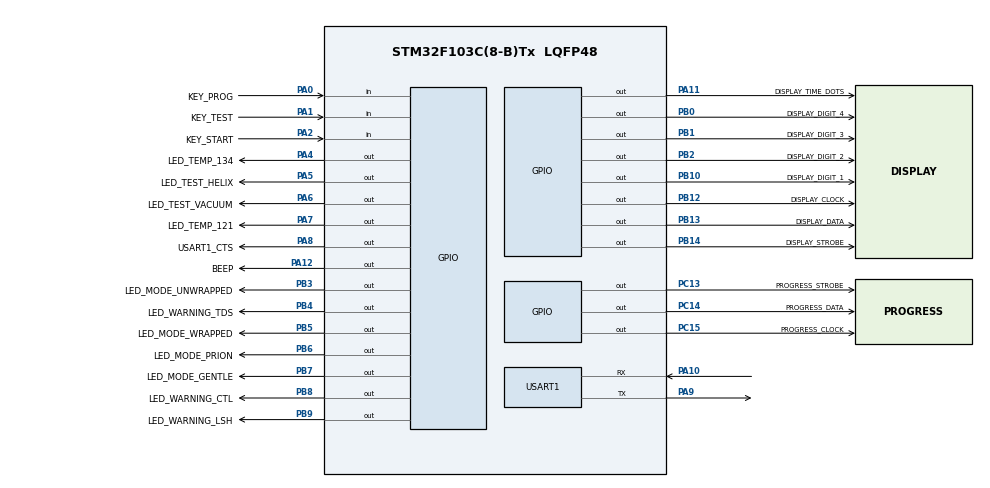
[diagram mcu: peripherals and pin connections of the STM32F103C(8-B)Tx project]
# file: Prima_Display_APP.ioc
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Dma.Request0=USART1_RX
Dma.USART1_RX.0.Direction=DMA_PERIPH_TO_MEMORY
Dma.USART1_RX.0.Instance=DMA1_Channel5
Dma.USART1_RX.0.MemDataAlignment=DMA_MDATAALIGN_BYTE
Dma.USART1_RX.0.MemInc=DMA_MINC_ENABLE
Dma.USART1_RX.0.Mode=DMA_NORMAL
Dma.USART1_RX.0.PeriphDataAlignment=DMA_PDATAALIGN_BYTE
Dma.USART1_RX.0.PeriphInc=DMA_PINC_DISABLE
Dma.USART1_RX.0.Priority=DMA_PRIORITY_LOW
FREERTOS.Queues01=qBeep,3,uint64_t,0,Dynamic,NULL,NULL;qSend,16,uint16_t,0,Dynamic,NULL,NULL;qReceive,16,uint16_t,0,Dynamic,NULL,NULL
FREERTOS.Tasks01=dispTask,0,128,StartDisplayTask,Default,NULL,Dynamic,NULL,NULL;dispBlinkTask,-3,128,StartDisplayBlinkTask,Default,NULL,Dynamic,NULL,NULL;dispSerialTask,-3,128,StartDisplaySerialReceiveTask,Default,NULL,Dynamic,NULL,NULL;buzzerTask,-3,128,StartBuzzerTask,Default,NULL,Dynamic,NULL,NULL
FREERTOS.configUSE_NEWLIB_REENTRANT=1
Mcu.Family=STM32F1
Mcu.Name=STM32F103C(8-B)Tx
Mcu.Package=LQFP48
NVIC.DMA1_Channel5_IRQn=true\:5\:0\:false\:false\:true\:true\:false\:true\:true
NVIC.PriorityGroup=NVIC_PRIORITYGROUP_4
NVIC.TIM3_IRQn=true\:15\:0\:false\:false\:true\:false\:false\:true\:true
NVIC.TimeBase=TIM3_IRQn
NVIC.TimeBaseIP=TIM3
NVIC.USART1_IRQn=true\:5\:0\:false\:false\:true\:true\:true\:true\:true
PA0-WKUP.GPIO_Label=KEY_PROG
PA0-WKUP.Signal=GPIO_Input
PA1.GPIO_Label=KEY_TEST
PA1.Signal=GPIO_Input
PA10.Mode=Asynchronous
PA10.Signal=USART1_RX
PA11.GPIO_Label=DISPLAY_TIME_DOTS
PA11.Signal=GPIO_Output
PA12.GPIO_Label=BEEP
PA12.Signal=GPIO_Output
PA13.Mode=Serial_Wire
PA13.Signal=SYS_JTMS-SWDIO
PA14.Mode=Serial_Wire
PA14.Signal=SYS_JTCK-SWCLK
PA2.GPIO_Label=KEY_START
PA2.Signal=GPIO_Input
PA4.GPIO_Label=LED_TEMP_134
PA4.Signal=GPIO_Output
PA5.GPIO_Label=LED_TEST_HELIX
PA5.Signal=GPIO_Output
PA6.GPIO_Label=LED_TEST_VACUUM
PA6.Signal=GPIO_Output
PA7.GPIO_Label=LED_TEMP_121
PA7.Signal=GPIO_Output
PA8.GPIO_Label=USART1_CTS
PA8.Signal=GPIO_Output
PA9.Mode=Asynchronous
PA9.Signal=USART1_TX
PB0.GPIO_Label=DISPLAY_DIGIT_4
PB0.Signal=GPIO_Output
PB1.GPIO_Label=DISPLAY_DIGIT_3
PB1.Signal=GPIO_Output
PB10.GPIO_Label=DISPLAY_DIGIT_1
PB10.Signal=GPIO_Output
PB12.GPIO_Label=DISPLAY_CLOCK
PB12.Signal=GPIO_Output
PB13.GPIO_Label=DISPLAY_DATA
PB13.Signal=GPIO_Output
PB14.GPIO_Label=DISPLAY_STROBE
PB14.Signal=GPIO_Output
PB2.GPIO_Label=DISPLAY_DIGIT_2
PB2.Signal=GPIO_Output
PB3.GPIO_Label=LED_MODE_UNWRAPPED
PB3.Signal=GPIO_Output
PB4.GPIO_Label=LED_WARNING_TDS
PB4.Signal=GPIO_Output
PB5.GPIO_Label=LED_MODE_WRAPPED
PB5.Signal=GPIO_Output
PB6.GPIO_Label=LED_MODE_PRION
PB6.Signal=GPIO_Output
PB7.GPIO_Label=LED_MODE_GENTLE
PB7.Signal=GPIO_Output
PB8.GPIO_Label=LED_WARNING_CTL
PB8.Signal=GPIO_Output
PB9.GPIO_Label=LED_WARNING_LSH
PB9.Signal=GPIO_Output
PC13-TAMPER-RTC.GPIO_Label=PROGRESS_STROBE
PC13-TAMPER-RTC.Signal=GPIO_Output
PC14-OSC32_IN.GPIO_Label=PROGRESS_DATA
PC14-OSC32_IN.Signal=GPIO_Output
PC15-OSC32_OUT.GPIO_Label=PROGRESS_CLOCK
PC15-OSC32_OUT.Signal=GPIO_Output
ProjectManager.HeapSize=0x200
ProjectManager.StackSize=0x400
ProjectManager.TargetToolchain=STM32CubeIDE
RCC.APB1Freq_Value=8000000
RCC.APB2Freq_Value=8000000
USART1.VirtualMode=VM_ASYNC
VP_FREERTOS_VS_CMSIS_V1.Mode=CMSIS_V1
VP_SYS_VS_tim3.Mode=TIM3
VP_TIM1_VS_ClockSourceINT.Mode=Internal
board=custom

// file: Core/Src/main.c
/* USER CODE BEGIN Header */
/**
  ******************************************************************************
  * @file           : main.c
  * @brief          : Main program body
  ******************************************************************************
  * @attention
  *
  * Copyright (c) 2022 STMicroelectronics.
  * All rights reserved.
  *
  * This software is licensed under terms that can be found in the LICENSE file
  * in the root directory of this software component.
  * If no LICENSE file comes with this software, it is provided AS-IS.
  *
  ******************************************************************************
  */
/* USER CODE END Header */
#include "main.h"

TIM_HandleTypeDef htim1;

UART_HandleTypeDef huart1;
DMA_HandleTypeDef hdma_usart1_rx;

osMessageQId qBeepHandle;
osMessageQId qSendHandle;
osMessageQId qReceiveHandle;

osThreadId dispTaskHandle;
osThreadId dispBlinkTaskHandle;
osThreadId dispSerialTaskHandle;
osThreadId buzzerTaskHandle;

void SystemClock_Config(void);
static void MX_GPIO_Init(void);
static void MX_DMA_Init(void);
static void MX_TIM1_Init(void);
static void MX_USART1_UART_Init(void);
void StartDisplayTask(void const * argument);
void StartDisplayBlinkTask(void const * argument);
void StartDisplaySerialReceiveTask(void const * argument);
void StartBuzzerTask(void const * argument);

/* USER CODE BEGIN 0 */

#define UART_BUFFER_SIZE 30
uint8_t UART_rxBuffer[UART_BUFFER_SIZE] = {0};

void HAL_UARTEx_RxEventCallback(UART_HandleTypeDef *huart, uint16_t Size) {
	//HAL_UART_Receive_DMA(p_activeUART, UART_rxBuffer, 3);

	HAL_UARTEx_ReceiveToIdle_DMA(huart, UART_rxBuffer, UART_BUFFER_SIZE); // Interrupt on receive buffer full or idle (end receive)
	__HAL_DMA_DISABLE_IT(&hdma_usart1_rx, DMA_IT_HT); // Disable half buffer received interrupt

	// Check for UART
	if (huart->Instance == huart1.Instance) {
		DisplaySerialReceive(UART_rxBuffer, Size);
	}

	// Receive again

}

/* USER CODE END 0 */

int main(void)
{

  /* MCU Configuration--------------------------------------------------------*/

  /* Reset of all peripherals, Initializes the Flash interface and the Systick. */
  HAL_Init();

  /* Configure the system clock */
  SystemClock_Config();

  /* Initialize all configured peripherals */
  MX_GPIO_Init();
  MX_DMA_Init();
  MX_TIM1_Init();
  MX_USART1_UART_Init();
  /* USER CODE BEGIN 2 */

  HAL_UARTEx_ReceiveToIdle_DMA(&huart1, UART_rxBuffer, UART_BUFFER_SIZE); // Interrupt on receive buffer full or idle (end receive)
  __HAL_DMA_DISABLE_IT(&hdma_usart1_rx, DMA_IT_HT); // Disable half buffer received interrupt

progressBarBits = 0x0;
PanelSetAll();

  /* USER CODE END 2 */

  /* Create the queue(s) */
  /* definition and creation of qBeep */
  osMessageQDef(qBeep, 3, uint64_t);
  qBeepHandle = osMessageCreate(osMessageQ(qBeep), NULL);

  /* definition and creation of qSend */
  osMessageQDef(qSend, 16, uint16_t);
  qSendHandle = osMessageCreate(osMessageQ(qSend), NULL);

  /* definition and creation of qReceive */
  osMessageQDef(qReceive, 16, uint16_t);
  qReceiveHandle = osMessageCreate(osMessageQ(qReceive), NULL);

  /* Create the thread(s) */
  /* definition and creation of dispTask */
  osThreadDef(dispTask, StartDisplayTask, osPriorityNormal, 0, 128);
  dispTaskHandle = osThreadCreate(osThread(dispTask), NULL);

  /* definition and creation of dispBlinkTask */
  osThreadDef(dispBlinkTask, StartDisplayBlinkTask, osPriorityIdle, 0, 128);
  dispBlinkTaskHandle = osThreadCreate(osThread(dispBlinkTask), NULL);

  /* definition and creation of dispSerialTask */
  osThreadDef(dispSerialTask, StartDisplaySerialReceiveTask, osPriorityIdle, 0, 128);
  dispSerialTaskHandle = osThreadCreate(osThread(dispSerialTask), NULL);

  /* definition and creation of buzzerTask */
  osThreadDef(buzzerTask, StartBuzzerTask, osPriorityIdle, 0, 128);
  buzzerTaskHandle = osThreadCreate(osThread(buzzerTask), NULL);

  /* Start scheduler */
  osKernelStart();

  /* We should never get here as control is now taken by the scheduler */
  /* Infinite loop */
  while (1)
  {

  }
}

void SystemClock_Config(void)
{
  RCC_OscInitTypeDef RCC_OscInitStruct = {0};
  RCC_ClkInitTypeDef RCC_ClkInitStruct = {0};

  /** Initializes the RCC Oscillators according to the specified parameters
  * in the RCC_OscInitTypeDef structure.
  */
  RCC_OscInitStruct.OscillatorType = RCC_OSCILLATORTYPE_HSI;
  RCC_OscInitStruct.HSIState = RCC_HSI_ON;
  RCC_OscInitStruct.HSICalibrationValue = RCC_HSICALIBRATION_DEFAULT;
  RCC_OscInitStruct.PLL.PLLState = RCC_PLL_NONE;
  if (HAL_RCC_OscConfig(&RCC_OscInitStruct) != HAL_OK)
  {
    Error_Handler();
  }

  /** Initializes the CPU, AHB and APB buses clocks
  */
  RCC_ClkInitStruct.ClockType = RCC_CLOCKTYPE_HCLK|RCC_CLOCKTYPE_SYSCLK
                              |RCC_CLOCKTYPE_PCLK1|RCC_CLOCKTYPE_PCLK2;
  RCC_ClkInitStruct.SYSCLKSource = RCC_SYSCLKSOURCE_HSI;
  RCC_ClkInitStruct.AHBCLKDivider = RCC_SYSCLK_DIV1;
  RCC_ClkInitStruct.APB1CLKDivider = RCC_HCLK_DIV1;
  RCC_ClkInitStruct.APB2CLKDivider = RCC_HCLK_DIV1;

  if (HAL_RCC_ClockConfig(&RCC_ClkInitStruct, FLASH_LATENCY_0) != HAL_OK)
  {
    Error_Handler();
  }
}

static void MX_TIM1_Init(void)
{

  TIM_ClockConfigTypeDef sClockSourceConfig = {0};
  TIM_MasterConfigTypeDef sMasterConfig = {0};

  htim1.Instance = TIM1;
  htim1.Init.Prescaler = 0;
  htim1.Init.CounterMode = TIM_COUNTERMODE_UP;
  htim1.Init.Period = 65535;
  htim1.Init.ClockDivision = TIM_CLOCKDIVISION_DIV1;
  htim1.Init.RepetitionCounter = 0;
  htim1.Init.AutoReloadPreload = TIM_AUTORELOAD_PRELOAD_DISABLE;
  if (HAL_TIM_Base_Init(&htim1) != HAL_OK)
  {
    Error_Handler();
  }
  sClockSourceConfig.ClockSource = TIM_CLOCKSOURCE_INTERNAL;
  if (HAL_TIM_ConfigClockSource(&htim1, &sClockSourceConfig) != HAL_OK)
  {
    Error_Handler();
  }
  sMasterConfig.MasterOutputTrigger = TIM_TRGO_RESET;
  sMasterConfig.MasterSlaveMode = TIM_MASTERSLAVEMODE_DISABLE;
  if (HAL_TIMEx_MasterConfigSynchronization(&htim1, &sMasterConfig) != HAL_OK)
  {
    Error_Handler();
  }

}

static void MX_USART1_UART_Init(void)
{

  huart1.Instance = USART1;
  huart1.Init.BaudRate = 115200;
  huart1.Init.WordLength = UART_WORDLENGTH_8B;
  huart1.Init.StopBits = UART_STOPBITS_1;
  huart1.Init.Parity = UART_PARITY_NONE;
  huart1.Init.Mode = UART_MODE_TX_RX;
  huart1.Init.HwFlowCtl = UART_HWCONTROL_NONE;
  huart1.Init.OverSampling = UART_OVERSAMPLING_16;
  if (HAL_UART_Init(&huart1) != HAL_OK)
  {
    Error_Handler();
  }

}

static void MX_DMA_Init(void)
{

  /* DMA controller clock enable */
  __HAL_RCC_DMA1_CLK_ENABLE();

  /* DMA interrupt init */
  /* DMA1_Channel5_IRQn interrupt configuration */
  HAL_NVIC_SetPriority(DMA1_Channel5_IRQn, 5, 0);
  HAL_NVIC_EnableIRQ(DMA1_Channel5_IRQn);

}

static void MX_GPIO_Init(void)
{
  GPIO_InitTypeDef GPIO_InitStruct = {0};

  /* GPIO Ports Clock Enable */
  __HAL_RCC_GPIOC_CLK_ENABLE();
  __HAL_RCC_GPIOA_CLK_ENABLE();
  __HAL_RCC_GPIOB_CLK_ENABLE();

  /*Configure GPIO pin Output Level */
  HAL_GPIO_WritePin(GPIOC, PROGRESS_STROBE_Pin|PROGRESS_DATA_Pin|PROGRESS_CLOCK_Pin, GPIO_PIN_RESET);

  /*Configure GPIO pin Output Level */
  HAL_GPIO_WritePin(GPIOA, LED_TEMP_134_Pin|LED_TEST_HELIX_Pin|LED_TEST_VACUUM_Pin|LED_TEMP_121_Pin
                          |USART1_CTS_Pin|DISPLAY_TIME_DOTS_Pin|BEEP_Pin, GPIO_PIN_RESET);

  /*Configure GPIO pin Output Level */
  HAL_GPIO_WritePin(GPIOB, DISPLAY_DIGIT_4_Pin|DISPLAY_DIGIT_3_Pin|DISPLAY_DIGIT_2_Pin|DISPLAY_DIGIT_1_Pin
                          |DISPLAY_CLOCK_Pin|DISPLAY_DATA_Pin|DISPLAY_STROBE_Pin|LED_MODE_UNWRAPPED_Pin
                          |LED_WARNING_TDS_Pin|LED_MODE_WRAPPED_Pin|LED_MODE_PRION_Pin|LED_MODE_GENTLE_Pin
                          |LED_WARNING_CTL_Pin|LED_WARNING_LSH_Pin, GPIO_PIN_RESET);

  /*Configure GPIO pins : PROGRESS_STROBE_Pin PROGRESS_DATA_Pin PROGRESS_CLOCK_Pin */
  GPIO_InitStruct.Pin = PROGRESS_STROBE_Pin|PROGRESS_DATA_Pin|PROGRESS_CLOCK_Pin;
  GPIO_InitStruct.Mode = GPIO_MODE_OUTPUT_PP;
  GPIO_InitStruct.Pull = GPIO_NOPULL;
  GPIO_InitStruct.Speed = GPIO_SPEED_FREQ_LOW;
  HAL_GPIO_Init(GPIOC, &GPIO_InitStruct);

  /*Configure GPIO pins : KEY_PROG_Pin KEY_TEST_Pin KEY_START_Pin */
  GPIO_InitStruct.Pin = KEY_PROG_Pin|KEY_TEST_Pin|KEY_START_Pin;
  GPIO_InitStruct.Mode = GPIO_MODE_INPUT;
  GPIO_InitStruct.Pull = GPIO_NOPULL;
  HAL_GPIO_Init(GPIOA, &GPIO_InitStruct);

  /*Configure GPIO pins : LED_TEMP_134_Pin LED_TEST_HELIX_Pin LED_TEST_VACUUM_Pin LED_TEMP_121_Pin
                           USART1_CTS_Pin DISPLAY_TIME_DOTS_Pin BEEP_Pin */
  GPIO_InitStruct.Pin = LED_TEMP_134_Pin|LED_TEST_HELIX_Pin|LED_TEST_VACUUM_Pin|LED_TEMP_121_Pin
                          |USART1_CTS_Pin|DISPLAY_TIME_DOTS_Pin|BEEP_Pin;
  GPIO_InitStruct.Mode = GPIO_MODE_OUTPUT_PP;
  GPIO_InitStruct.Pull = GPIO_NOPULL;
  GPIO_InitStruct.Speed = GPIO_SPEED_FREQ_LOW;
  HAL_GPIO_Init(GPIOA, &GPIO_InitStruct);

  /*Configure GPIO pins : DISPLAY_DIGIT_4_Pin DISPLAY_DIGIT_3_Pin DISPLAY_DIGIT_2_Pin DISPLAY_DIGIT_1_Pin
                           DISPLAY_CLOCK_Pin DISPLAY_DATA_Pin DISPLAY_STROBE_Pin LED_MODE_UNWRAPPED_Pin
                           LED_WARNING_TDS_Pin LED_MODE_WRAPPED_Pin LED_MODE_PRION_Pin LED_MODE_GENTLE_Pin
                           LED_WARNING_CTL_Pin LED_WARNING_LSH_Pin */
  GPIO_InitStruct.Pin = DISPLAY_DIGIT_4_Pin|DISPLAY_DIGIT_3_Pin|DISPLAY_DIGIT_2_Pin|DISPLAY_DIGIT_1_Pin
                          |DISPLAY_CLOCK_Pin|DISPLAY_DATA_Pin|DISPLAY_STROBE_Pin|LED_MODE_UNWRAPPED_Pin
                          |LED_WARNING_TDS_Pin|LED_MODE_WRAPPED_Pin|LED_MODE_PRION_Pin|LED_MODE_GENTLE_Pin
                          |LED_WARNING_CTL_Pin|LED_WARNING_LSH_Pin;
  GPIO_InitStruct.Mode = GPIO_MODE_OUTPUT_PP;
  GPIO_InitStruct.Pull = GPIO_NOPULL;
  GPIO_InitStruct.Speed = GPIO_SPEED_FREQ_LOW;
  HAL_GPIO_Init(GPIOB, &GPIO_InitStruct);

}

void StartDisplayTask(void const * argument)
{
  /* USER CODE BEGIN 5 */
  /* Infinite loop */

	//Beep(2, 100, 100);

	//progressBarBits = 0b0000000000000000;

  for(;;)
  {
    osDelay(1);
  }
  /* USER CODE END 5 */
}

void StartDisplayBlinkTask(void const * argument)
{
  /* USER CODE BEGIN StartDisplayBlinkTask */
  /* Infinite loop */
	//Beep(1, 100, 100);

//	struct serialKeys_s a;
//	a.keysPressed = 0x41;
	//a.CRC16 = 0x4242;

  for(;;)
  {
//	  uint8_t Test[] = "Hello World !!!\r\n"; //Data to send
//	  HAL_GPIO_WritePin(USART1_CTS_GPIO_Port, USART1_CTS_Pin, 1);
//	  HAL_UART_Transmit(&huart1,Test,sizeof(Test),10);// Sending in normal mode
//	  HAL_GPIO_WritePin(USART1_CTS_GPIO_Port, USART1_CTS_Pin, 0);
	  //HAL_Delay(1000);
//	  SendKeysSerial(&a);
//	  sendSerialData(&a);
    osDelay(1000);
  }
  /* USER CODE END StartDisplayBlinkTask */
}

void StartDisplaySerialReceiveTask(void const * argument)
{
  /* USER CODE BEGIN StartDisplaySerialReceiveTask */
  /* Infinite loop */
//	_task_DisplaySerialReceive();

  for(;;)
  {
    osDelay(1);
  }
  /* USER CODE END StartDisplaySerialReceiveTask */
}

void StartBuzzerTask(void const * argument)
{
  /* USER CODE BEGIN StartBuzzerTask */
  /* Infinite loop */
	BeepTask();
  for(;;)
  {
    osDelay(1);
  }
  /* USER CODE END StartBuzzerTask */
}

void HAL_TIM_PeriodElapsedCallback(TIM_HandleTypeDef *htim)
{
  if (htim->Instance == TIM3) {
    HAL_IncTick();
  }
}

void Error_Handler(void)
{
  __disable_irq();
  while (1)
  {
  }
}
